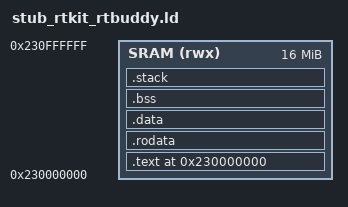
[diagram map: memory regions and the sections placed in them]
/**
 * Autogenerated Linker Script for stub_rtkit_rtbuddy
 * Origin: 0x230000000, Length: 16M
 */
OUTPUT_FORMAT("elf64-littleaarch64")
OUTPUT_ARCH(aarch64)
ENTRY(_start)

MEMORY
{
    SRAM (rwx) : ORIGIN = 0x230000000, LENGTH = 16M
}

SECTIONS
{
    . = ORIGIN(SRAM);

    .text : {
        KEEP(*(.text.boot))
        *(.text .text.*)
    } > SRAM

    .rodata : {
        *(.rodata .rodata.*)
    } > SRAM

    .data : {
        *(.data .data.*)
    } > SRAM

    .bss : ALIGN(16) {
        _bss_start = .;
        *(.bss .bss.*)
        *(COMMON)
        _bss_end = .;
    } > SRAM

    .stack : ALIGN(16) {
        _stack_bottom = .;
        . += 0x10000; /* 64 KB Stack */
        _stack_top = .;
    } > SRAM

    /DISCARD/ : {
        *(.comment)
        *(.note*)
        *(.eh_frame*)
    }
}
